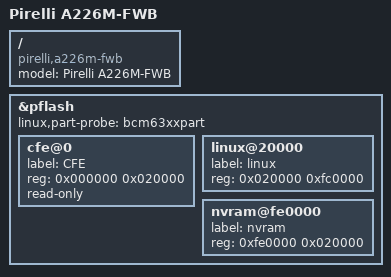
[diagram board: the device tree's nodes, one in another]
/dts-v1/;

/include/ "bcm6358.dtsi"

/ {
	model = "Pirelli A226M-FWB";
	compatible = "pirelli,a226m-fwb", "brcm,bcm6358";
};

&pflash {
	status = "ok";

	linux,part-probe = "bcm63xxpart";

	cfe@0 {
		label = "CFE";
		reg = <0x000000 0x020000>;
		read-only;
	};

	linux@20000 {
		label = "linux";
		reg = <0x020000 0xfc0000>;
	};

	nvram@fe0000 {
		label = "nvram";
		reg = <0xfe0000 0x020000>;
	};
};
